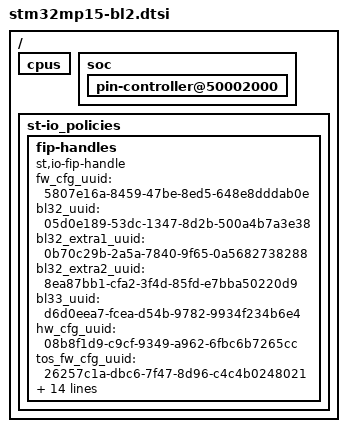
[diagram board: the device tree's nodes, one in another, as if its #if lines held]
// SPDX-License-Identifier: (GPL-2.0+ OR BSD-3-Clause)
/*
 * Copyright (C) STMicroelectronics 2020-2021 - All Rights Reserved
 */

/ {
	cpus {
		/delete-node/ cpu@1;
	};

	/delete-node/ psci;

	soc {
		/delete-node/ timer@40006000;
		/delete-node/ timer@44006000;
		/delete-node/ pwr_mcu@50001014;
		/delete-node/ cryp@54001000;
		/delete-node/ rng@54003000;
		/delete-node/ spi@5c001000;
		/delete-node/ rtc@5c004000;
		/delete-node/ etzpc@5c007000;
		/delete-node/ stgen@5c008000;
		/delete-node/ i2c@5c009000;
		/delete-node/ tamp@5c00a000;

		pin-controller@50002000 {
			/delete-node/ rtc-out2-rmp-pins-0;
		};
	};

#if !STM32MP_USE_STM32IMAGE
	/*
	 * UUID's here are UUID RFC 4122 compliant meaning fieds are stored in
	 * network order (big endian)
	 */

	st-io_policies {
		fip-handles {
			compatible = "st,io-fip-handle";
			fw_cfg_uuid = "5807e16a-8459-47be-8ed5-648e8dddab0e";
			bl32_uuid = "05d0e189-53dc-1347-8d2b-500a4b7a3e38";
			bl32_extra1_uuid = "0b70c29b-2a5a-7840-9f65-0a5682738288";
			bl32_extra2_uuid = "8ea87bb1-cfa2-3f4d-85fd-e7bba50220d9";
			bl33_uuid = "d6d0eea7-fcea-d54b-9782-9934f234b6e4";
			hw_cfg_uuid = "08b8f1d9-c9cf-9349-a962-6fbc6b7265cc";
			tos_fw_cfg_uuid = "26257c1a-dbc6-7f47-8d96-c4c4b0248021";
			nt_fw_cfg_uuid = "28da9815-93e8-7e44-ac66-1aaf801550f9";
			t_key_cert_uuid = "827ee890-f860-e411-a1b4-777a21b4f94c";
			t_boot_fw_cert_uuid = "d6e269ea-5d63-e411-8d8c-9fbabe9956a5";
			tos_fw_key_cert_uuid = "9477d603-fb60-e411-85dd-b7105b8cee04";
			nt_fw_key_cert_uuid = "8ad5832a-fb60-e411-8aaf-df30bbc49859";
			tos_fw_content_cert_uuid = "a49f4411-5e63-e411-8728-3f05722af33d";
			nt_fw_content_cert_uuid = "8ec4c1f3-5d63-e411-a7a9-87ee40b23fa7";
		};
	};
#endif /* !STM32MP_USE_STM32IMAGE */
};
